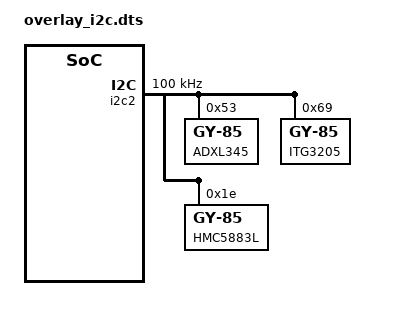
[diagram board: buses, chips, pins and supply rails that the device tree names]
/dts-v1/;
/plugin/;

fragment@0 {
    target = <&i2c2>;
    __overlay__ {
        status = "okay";
        clock-frequency = <100000>;
        pinctrl-0 = <&i2c2_pins>;
        pinctrl-names = "default";
        
        ADXL345: ADXL345@53 {
            compatible = "GY-85";
            reg = <0x53>;
        };
        ITG3205: ITG3205@69 {
            compatible = "GY-85";
            reg = <0x69>;
        };
        HMC5883L: HMC5883L@1E {
            compatible = "GY-85";
            reg = <0x1E>;
        };
    }
}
